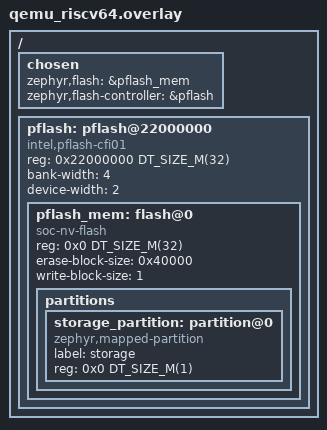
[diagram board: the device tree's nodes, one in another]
/*
 * Copyright (c) 2026 Analog Devices, Inc.
 * SPDX-License-Identifier: Apache-2.0
 *
 * DTS overlay for Intel CFI01 pflash driver test on qemu_riscv64
 */

#include <mem.h>

/ {
	chosen {
		zephyr,flash = &pflash_mem;
		zephyr,flash-controller = &pflash;
	};

	/* Add Intel CFI01 pflash device */
	pflash: pflash@22000000 {
		compatible = "intel,pflash-cfi01";
		reg = <0x22000000 DT_SIZE_M(32)>;
		bank-width = <4>;
		#address-cells = <1>;
		#size-cells = <1>;

		device-width = <2>;

		pflash_mem: flash@0 {
			compatible = "soc-nv-flash";
			reg = <0x0 DT_SIZE_M(32)>;
			ranges = <0x0 0x0 DT_SIZE_M(32)>;
			erase-block-size = <0x40000>;
			write-block-size = <1>;
			#address-cells = <1>;
			#size-cells = <1>;

			partitions {
				ranges;
				#address-cells = <1>;
				#size-cells = <1>;

				storage_partition: partition@0 {
					compatible = "zephyr,mapped-partition";
					label = "storage";
					reg = <0x0 DT_SIZE_M(1)>;
				};
			};
		};
	};
};
